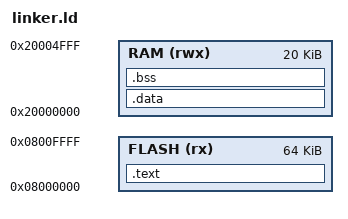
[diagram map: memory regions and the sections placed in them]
ENTRY(_start)

MEMORY
{
    FLASH (rx) : ORIGIN = 0x08000000, LENGTH = 64K
    RAM (rwx) : ORIGIN = 0x20000000, LENGTH = 20K
}

SECTIONS
{
    .text :
    {
        KEEP(*(.isr_vector))
        *(.text*)
        *(.rodata*)
    } > FLASH

    .data : AT(ADDR(.text) + SIZEOF(.text))
    {
        *(.data*)
    } > RAM

    .bss :
    {
        *(.bss*)
        *(COMMON)
    } > RAM
}
ENTRY(_start)

MEMORY
{
    FLASH (rx) : ORIGIN = 0x08000000, LENGTH = 64K
    RAM   (rwx) : ORIGIN = 0x20000000, LENGTH = 20K
}

SECTIONS
{
    .text :
    {
        KEEP(*(.isr_vector))   /* vector table */
        *(.text*)
        *(.rodata*)
    } > FLASH

    .data : AT(ADDR(.text) + SIZEOF(.text))
    {
        *(.data*)
    } > RAM

    .bss (NOLOAD) :
    {
        __bss_start__ = .;
        *(.bss*)
        *(COMMON)
        __bss_end__ = .;
    } > RAM
}
